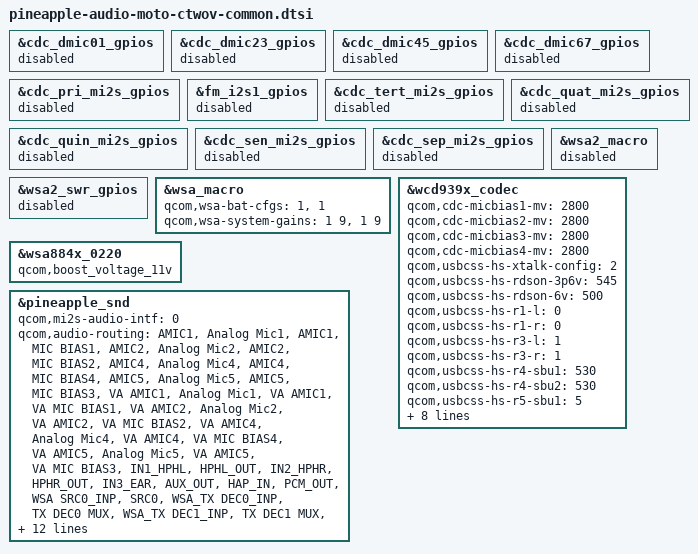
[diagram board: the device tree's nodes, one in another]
/* This is original from pineapple-audio-mtp.dtsi */

#include "pineapple-audio-overlay.dtsi"

&cdc_dmic01_gpios {
    status = "disabled";
};

&cdc_dmic23_gpios {
    status = "disabled";
};

&cdc_dmic45_gpios {
    status = "disabled";
};

&cdc_dmic67_gpios {
    status = "disabled";
};

&cdc_pri_mi2s_gpios {
	status = "disabled";
};

&fm_i2s1_gpios {
	status = "disabled";
};

&cdc_tert_mi2s_gpios {
	status = "disabled";
};

&cdc_quat_mi2s_gpios {
	status = "disabled";
};

&cdc_quin_mi2s_gpios {
	status = "disabled";
};

&cdc_sen_mi2s_gpios {
	status = "disabled";
};

&cdc_sep_mi2s_gpios {
	status = "disabled";
};

&wsa2_macro {
	status = "disabled";
};

&wsa2_swr_gpios {
    status = "disabled";
};

/*  CONFIG_1S: BST_CFG1 & BST_CFG0 pin are both connected to GND */
&wsa_macro {
    qcom,wsa-bat-cfgs= <1>, <1>;
    qcom,wsa-system-gains= <1 9>, <1 9>;
};

/* copied from pineapple-audio-qrd.dtsi */
&wcd939x_codec {
        qcom,cdc-micbias1-mv = <2800>;
        qcom,cdc-micbias2-mv = <2800>;
        qcom,cdc-micbias3-mv = <2800>;
        qcom,cdc-micbias4-mv = <2800>;

        /* 0 for digital crosstalk disabled,
        * 1 for digital crosstalk with local sensed a-xtalk enabled, and
        * 2 for digital crosstalk with remote sensed a-xtalk enabled.
        */
        qcom,usbcss-hs-xtalk-config = <2>;
        qcom,usbcss-hs-rdson-3p6v = <545>;
        qcom,usbcss-hs-rdson-6v = <500>;
        qcom,usbcss-hs-r1-l = <0>;
        qcom,usbcss-hs-r1-r = <0>;
        qcom,usbcss-hs-r3-l = <1>;
        qcom,usbcss-hs-r3-r = <1>;
        qcom,usbcss-hs-r4-sbu1 = <530>;
        qcom,usbcss-hs-r4-sbu2 = <530>;
        qcom,usbcss-hs-r5-sbu1 = <5>;
        qcom,usbcss-hs-r5-sbu2 = <5>;
        qcom,usbcss-hs-r6-sbu1 = <1>;
        qcom,usbcss-hs-r6-sbu2 = <1>;
        qcom,usbcss-hs-r7-sbu1 = <5>;
        qcom,usbcss-hs-r7-sbu2 = <5>;
        qcom,usbcss-hs-rcom-margin = <500>;
        qcom,usbcss-hs-diff-slope = <9898>;
        qcom,usbcss-hs-lin-k-aud = <13>;
};

&wsa884x_0220 {
       qcom,boost_voltage_11v;
};

&pineapple_snd {
        qcom,mi2s-audio-intf = <0>;
		qcom,audio-routing =
			"AMIC1", "Analog Mic1",
			"AMIC1", "MIC BIAS1",
			"AMIC2", "Analog Mic2",
			"AMIC2", "MIC BIAS2",
			"AMIC4", "Analog Mic4",
			"AMIC4", "MIC BIAS4",
			"AMIC5", "Analog Mic5",
			"AMIC5", "MIC BIAS3",
			"VA AMIC1", "Analog Mic1",
			"VA AMIC1", "VA MIC BIAS1",
			"VA AMIC2", "Analog Mic2",
			"VA AMIC2", "VA MIC BIAS2",
			"VA AMIC4", "Analog Mic4",
			"VA AMIC4", "VA MIC BIAS4",
			"VA AMIC5", "Analog Mic5",
			"VA AMIC5", "VA MIC BIAS3",
			"IN1_HPHL", "HPHL_OUT",
			"IN2_HPHR", "HPHR_OUT",
			"IN3_EAR", "AUX_OUT",
			"HAP_IN", "PCM_OUT",
			"WSA SRC0_INP", "SRC0",
			"WSA_TX DEC0_INP", "TX DEC0 MUX",
			"WSA_TX DEC1_INP", "TX DEC1 MUX",
			"RX_TX DEC0_INP", "TX DEC0 MUX",
			"RX_TX DEC1_INP", "TX DEC1 MUX",
			"RX_TX DEC2_INP", "TX DEC2 MUX",
			"RX_TX DEC3_INP", "TX DEC3 MUX",
			"SpkrLeft IN", "WSA_SPK1 OUT",
			"SpkrRight IN", "WSA_SPK2 OUT",
			"TX SWR_INPUT", "WCD_TX_OUTPUT",
			"VA SWR_INPUT", "VA_SWR_CLK",
			"VA SWR_INPUT", "WCD_TX_OUTPUT",
			"VA_AIF1 CAP", "VA_SWR_CLK",
			"VA_AIF2 CAP", "VA_SWR_CLK",
			"VA_AIF3 CAP", "VA_SWR_CLK";

	qcom,msm-mbhc-usbc-audio-supported = <1>;
	qcom,msm-mbhc-hphl-swh = <0>;
	qcom,msm-mbhc-gnd-swh = <0>;
	qcom,wcd-disable-legacy-surge;
};
